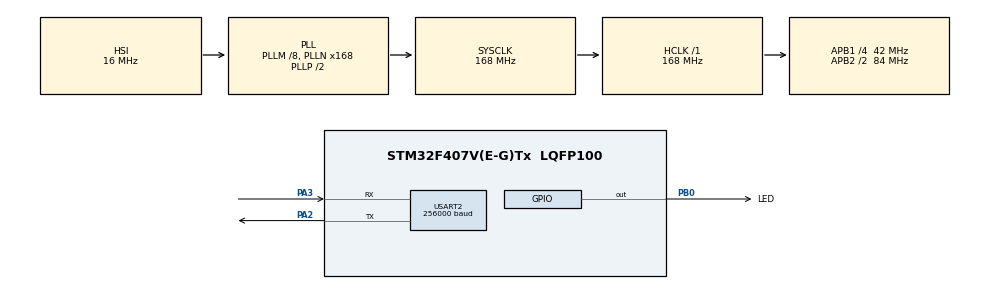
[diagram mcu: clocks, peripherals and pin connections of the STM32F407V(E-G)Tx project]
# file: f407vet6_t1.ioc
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ADC1.Channel-0\#ChannelRegularConversion=ADC_CHANNEL_TEMPSENSOR
ADC1.Channel-1\#ChannelRegularConversion=ADC_CHANNEL_VREFINT
ADC1.Channel-2\#ChannelRegularConversion=ADC_CHANNEL_VBAT
ADC1.ClockPrescaler=ADC_CLOCK_SYNC_PCLK_DIV8
ADC1.ContinuousConvMode=ENABLE
ADC1.DMAContinuousRequests=ENABLE
ADC1.NbrOfConversion=3
ADC1.NbrOfConversionFlag=1
ADC1.Rank-0\#ChannelRegularConversion=1
ADC1.Rank-1\#ChannelRegularConversion=2
ADC1.Rank-2\#ChannelRegularConversion=3
ADC1.SamplingTime-0\#ChannelRegularConversion=ADC_SAMPLETIME_480CYCLES
ADC1.SamplingTime-1\#ChannelRegularConversion=ADC_SAMPLETIME_480CYCLES
ADC1.SamplingTime-2\#ChannelRegularConversion=ADC_SAMPLETIME_480CYCLES
ADC1.ScanConvMode=ENABLE
ADC1.master=1
Dma.ADC1.2.Direction=DMA_PERIPH_TO_MEMORY
Dma.ADC1.2.FIFOMode=DMA_FIFOMODE_DISABLE
Dma.ADC1.2.Instance=DMA2_Stream0
Dma.ADC1.2.MemDataAlignment=DMA_MDATAALIGN_HALFWORD
Dma.ADC1.2.MemInc=DMA_MINC_ENABLE
Dma.ADC1.2.Mode=DMA_CIRCULAR
Dma.ADC1.2.PeriphDataAlignment=DMA_PDATAALIGN_HALFWORD
Dma.ADC1.2.PeriphInc=DMA_PINC_DISABLE
Dma.ADC1.2.Priority=DMA_PRIORITY_LOW
Dma.Request0=USART2_RX
Dma.Request1=USART2_TX
Dma.Request2=ADC1
Dma.USART2_RX.0.Direction=DMA_PERIPH_TO_MEMORY
Dma.USART2_RX.0.FIFOMode=DMA_FIFOMODE_DISABLE
Dma.USART2_RX.0.Instance=DMA1_Stream5
Dma.USART2_RX.0.MemDataAlignment=DMA_MDATAALIGN_BYTE
Dma.USART2_RX.0.MemInc=DMA_MINC_ENABLE
Dma.USART2_RX.0.Mode=DMA_NORMAL
Dma.USART2_RX.0.PeriphDataAlignment=DMA_PDATAALIGN_BYTE
Dma.USART2_RX.0.PeriphInc=DMA_PINC_DISABLE
Dma.USART2_RX.0.Priority=DMA_PRIORITY_LOW
Dma.USART2_TX.1.Direction=DMA_MEMORY_TO_PERIPH
Dma.USART2_TX.1.FIFOMode=DMA_FIFOMODE_DISABLE
Dma.USART2_TX.1.Instance=DMA1_Stream6
Dma.USART2_TX.1.MemDataAlignment=DMA_MDATAALIGN_BYTE
Dma.USART2_TX.1.MemInc=DMA_MINC_ENABLE
Dma.USART2_TX.1.Mode=DMA_NORMAL
Dma.USART2_TX.1.PeriphDataAlignment=DMA_PDATAALIGN_BYTE
Dma.USART2_TX.1.PeriphInc=DMA_PINC_DISABLE
Dma.USART2_TX.1.Priority=DMA_PRIORITY_LOW
Mcu.Family=STM32F4
Mcu.Name=STM32F407V(E-G)Tx
Mcu.Package=LQFP100
NVIC.DMA1_Stream5_IRQn=true\:0\:0\:false\:false\:true\:false
NVIC.DMA1_Stream6_IRQn=true\:0\:0\:false\:false\:true\:false
NVIC.DMA2_Stream0_IRQn=true\:0\:0\:false\:false\:true\:false
NVIC.PriorityGroup=NVIC_PRIORITYGROUP_4
PA13.Mode=Trace_Asynchronous_SW
PA13.Signal=SYS_JTMS-SWDIO
PA14.Mode=Trace_Asynchronous_SW
PA14.Signal=SYS_JTCK-SWCLK
PA2.Mode=Asynchronous
PA2.Signal=USART2_TX
PA3.Mode=Asynchronous
PA3.Signal=USART2_RX
PB0.GPIO_Label=LED
PB0.Signal=GPIO_Output
PB3.Mode=Trace_Asynchronous_SW
PB3.Signal=SYS_JTDO-SWO
PH0-OSC_IN.Mode=HSE-External-Oscillator
PH0-OSC_IN.Signal=RCC_OSC_IN
PH1-OSC_OUT.Mode=HSE-External-Oscillator
PH1-OSC_OUT.Signal=RCC_OSC_OUT
ProjectManager.HeapSize=0x200
ProjectManager.StackSize=0x2000
ProjectManager.TargetToolchain=SW4STM32
RCC.48MHZClocksFreq_Value=48000000
RCC.AHBFreq_Value=168000000
RCC.APB1CLKDivider=RCC_HCLK_DIV4
RCC.APB1Freq_Value=42000000
RCC.APB1TimFreq_Value=84000000
RCC.APB2CLKDivider=RCC_HCLK_DIV2
RCC.APB2Freq_Value=84000000
RCC.APB2TimFreq_Value=168000000
RCC.CortexFreq_Value=168000000
RCC.HCLKFreq_Value=168000000
RCC.HSE_VALUE=8000000
RCC.HSI_VALUE=16000000
RCC.LSE_VALUE=32768
RCC.PLLM=8
RCC.PLLN=168
RCC.PLLQ=7
RCC.SYSCLKFreq_VALUE=168000000
RCC.SYSCLKSource=RCC_SYSCLKSOURCE_PLLCLK
RCC.VCOOutputFreq_Value=336000000
USART2.BaudRate=256000
USART2.VirtualMode=VM_ASYNC
VP_ADC1_TempSens_Input.Mode=IN-TempSens
VP_ADC1_Vbat_Input.Mode=IN-Vbat
VP_ADC1_Vref_Input.Mode=IN-Vrefint
VP_CRC_VS_CRC.Mode=CRC_Activate
VP_RNG_VS_RNG.Mode=RNG_Activate
VP_RTC_VS_RTC_Activate.Mode=RTC_Enabled
VP_RTC_VS_RTC_Calendar.Mode=RTC_Calendar
board=f407vet6_t1

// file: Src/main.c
/**
  ******************************************************************************
  * File Name          : main.c
  * Description        : Main program body
  ******************************************************************************
  ** This notice applies to any and all portions of this file
  * that are not between comment pairs USER CODE BEGIN and
  * USER CODE END. Other portions of this file, whether
  * inserted by the user or by software development tools
  * are owned by their respective copyright owners.
  *
  * COPYRIGHT(c) 2017 STMicroelectronics
  *
  * Redistribution and use in source and binary forms, with or without modification,
  * are permitted provided that the following conditions are met:
  *   1. Redistributions of source code must retain the above copyright notice,
  *      this list of conditions and the following disclaimer.
  *   2. Redistributions in binary form must reproduce the above copyright notice,
  *      this list of conditions and the following disclaimer in the documentation
  *      and/or other materials provided with the distribution.
  *   3. Neither the name of STMicroelectronics nor the names of its contributors
  *      may be used to endorse or promote products derived from this software
  *      without specific prior written permission.
  *
  * THIS SOFTWARE IS PROVIDED BY THE COPYRIGHT HOLDERS AND CONTRIBUTORS "AS IS"
  * AND ANY EXPRESS OR IMPLIED WARRANTIES, INCLUDING, BUT NOT LIMITED TO, THE
  * IMPLIED WARRANTIES OF MERCHANTABILITY AND FITNESS FOR A PARTICULAR PURPOSE ARE
  * DISCLAIMED. IN NO EVENT SHALL THE COPYRIGHT HOLDER OR CONTRIBUTORS BE LIABLE
  * FOR ANY DIRECT, INDIRECT, INCIDENTAL, SPECIAL, EXEMPLARY, OR CONSEQUENTIAL
  * DAMAGES (INCLUDING, BUT NOT LIMITED TO, PROCUREMENT OF SUBSTITUTE GOODS OR
  * SERVICES; LOSS OF USE, DATA, OR PROFITS; OR BUSINESS INTERRUPTION) HOWEVER
  * CAUSED AND ON ANY THEORY OF LIABILITY, WHETHER IN CONTRACT, STRICT LIABILITY,
  * OR TORT (INCLUDING NEGLIGENCE OR OTHERWISE) ARISING IN ANY WAY OUT OF THE USE
  * OF THIS SOFTWARE, EVEN IF ADVISED OF THE POSSIBILITY OF SUCH DAMAGE.
  *
  ******************************************************************************
  */

#include "main.h"
#include "stm32f4xx_hal.h"
#include "adc.h"
#include "crc.h"
#include "dma.h"
#include "rng.h"
#include "rtc.h"
#include "usart.h"
#include "gpio.h"

/* USER CODE BEGIN PV */
/* Private variables ---------------------------------------------------------*/
__IO uint16_t g_ADCBuf[3];
/* USER CODE END PV */

void SystemClock_Config(void);

/* USER CODE BEGIN PFP */
/* Private function prototypes -----------------------------------------------*/

/* USER CODE END PFP */

/* USER CODE BEGIN 0 */
#if defined(__ARMCC_VERSION)
int stdout_putchar (int ch)
{
	uint8_t c = ch;
	HAL_UART_Transmit(&huart2, &c, 1, 1);
	return ch;
}
#else
int write (int fd, const void *buf, size_t count)
{
	for(uint32_t i=0; i<count; ++i)
	{
		HAL_UART_Transmit(&huart2, buf+i, 1, 1);
	}
	return count;
}
int _write (int fd, const void *buf, size_t count)
{
	for(uint32_t i=0; i<count; ++i)
	{
		HAL_UART_Transmit(&huart2, buf+i, 1, 1);
	}
	return count;
}
#endif
/* USER CODE END 0 */

int original_main(void)
{

  /* MCU Configuration----------------------------------------------------------*/

  /* Reset of all peripherals, Initializes the Flash interface and the Systick. */
  HAL_Init();

  /* Configure the system clock */
  SystemClock_Config();

  /* Initialize all configured peripherals */
  MX_GPIO_Init();
  MX_DMA_Init();
  MX_ADC1_Init();
  MX_CRC_Init();
  MX_RNG_Init();
  MX_RTC_Init();
  MX_USART2_UART_Init();

  /* USER CODE BEGIN 2 */
	printf("F407 Coremark @ %u Hz\n", SystemCoreClock);
	HAL_ADC_Start_DMA(&hadc1, (uint32_t*)g_ADCBuf, 3);
  /* USER CODE END 2 */

  /* Infinite loop */
  /* USER CODE BEGIN WHILE */
//  while (1)
//  {
//		HAL_GPIO_TogglePin(LED_GPIO_Port, LED_Pin);
//		printf("%u %u %u\n", g_ADCBuf[0], g_ADCBuf[1], g_ADCBuf[2]);
//		HAL_Delay(500);
  /* USER CODE END WHILE */

  /* USER CODE BEGIN 3 */

//  }
	return 0;
  /* USER CODE END 3 */

}

/** System Clock Configuration
*/
void SystemClock_Config(void)
{

  RCC_OscInitTypeDef RCC_OscInitStruct;
  RCC_ClkInitTypeDef RCC_ClkInitStruct;
  RCC_PeriphCLKInitTypeDef PeriphClkInitStruct;

    /**Configure the main internal regulator output voltage
    */
  __HAL_RCC_PWR_CLK_ENABLE();

  __HAL_PWR_VOLTAGESCALING_CONFIG(PWR_REGULATOR_VOLTAGE_SCALE1);

    /**Initializes the CPU, AHB and APB busses clocks
    */
  RCC_OscInitStruct.OscillatorType = RCC_OSCILLATORTYPE_HSI|RCC_OSCILLATORTYPE_LSI;
  RCC_OscInitStruct.HSIState = RCC_HSI_ON;
  RCC_OscInitStruct.HSICalibrationValue = 16;
  RCC_OscInitStruct.LSIState = RCC_LSI_ON;
  RCC_OscInitStruct.PLL.PLLState = RCC_PLL_ON;
  RCC_OscInitStruct.PLL.PLLSource = RCC_PLLSOURCE_HSI;
  RCC_OscInitStruct.PLL.PLLM = 8;
  RCC_OscInitStruct.PLL.PLLN = 168;
  RCC_OscInitStruct.PLL.PLLP = RCC_PLLP_DIV2;
  RCC_OscInitStruct.PLL.PLLQ = 7;
  if (HAL_RCC_OscConfig(&RCC_OscInitStruct) != HAL_OK)
  {
    _Error_Handler(__FILE__, __LINE__);
  }

    /**Initializes the CPU, AHB and APB busses clocks
    */
  RCC_ClkInitStruct.ClockType = RCC_CLOCKTYPE_HCLK|RCC_CLOCKTYPE_SYSCLK
                              |RCC_CLOCKTYPE_PCLK1|RCC_CLOCKTYPE_PCLK2;
  RCC_ClkInitStruct.SYSCLKSource = RCC_SYSCLKSOURCE_PLLCLK;
  RCC_ClkInitStruct.AHBCLKDivider = RCC_SYSCLK_DIV1;
  RCC_ClkInitStruct.APB1CLKDivider = RCC_HCLK_DIV4;
  RCC_ClkInitStruct.APB2CLKDivider = RCC_HCLK_DIV2;

  if (HAL_RCC_ClockConfig(&RCC_ClkInitStruct, FLASH_LATENCY_5) != HAL_OK)
  {
    _Error_Handler(__FILE__, __LINE__);
  }

  PeriphClkInitStruct.PeriphClockSelection = RCC_PERIPHCLK_RTC;
  PeriphClkInitStruct.RTCClockSelection = RCC_RTCCLKSOURCE_LSI;
  if (HAL_RCCEx_PeriphCLKConfig(&PeriphClkInitStruct) != HAL_OK)
  {
    _Error_Handler(__FILE__, __LINE__);
  }

    /**Configure the Systick interrupt time
    */
  HAL_SYSTICK_Config(HAL_RCC_GetHCLKFreq()/1000);

    /**Configure the Systick
    */
  HAL_SYSTICK_CLKSourceConfig(SYSTICK_CLKSOURCE_HCLK);

  /* SysTick_IRQn interrupt configuration */
  HAL_NVIC_SetPriority(SysTick_IRQn, 0, 0);
}

void _Error_Handler(char * file, int line)
{
  while(1)
  {
  }
}

/************************ (C) COPYRIGHT STMicroelectronics *****END OF FILE****/
